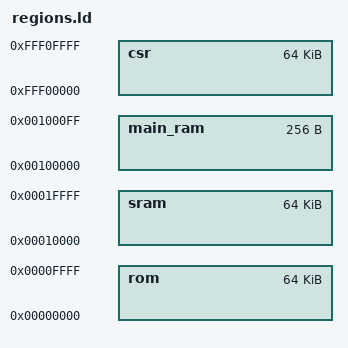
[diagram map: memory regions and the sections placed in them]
MEMORY {
	rom : ORIGIN = 0x00000000, LENGTH = 0x00010000
	sram : ORIGIN = 0x00010000, LENGTH = 0x00010000
	main_ram : ORIGIN = 0x00100000, LENGTH = 0x00000100
	csr : ORIGIN = 0xfff00000, LENGTH = 0x00010000
}
